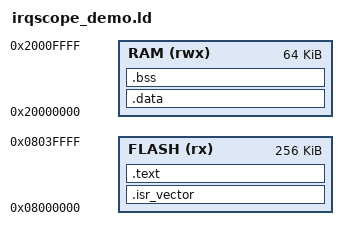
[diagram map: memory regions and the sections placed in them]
ENTRY(Reset_Handler)

MEMORY
{
    FLASH (rx)  : ORIGIN = 0x08000000, LENGTH = 256K
    RAM   (rwx) : ORIGIN = 0x20000000, LENGTH = 64K
}

__stack_top = ORIGIN(RAM) + LENGTH(RAM);

SECTIONS
{
    .isr_vector ORIGIN(FLASH) : ALIGN(128)
    {
        KEEP(*(.isr_vector))
    } > FLASH

    .text : ALIGN(4)
    {
        *(.text*)
        *(.rodata*)
        . = ALIGN(4);
        _etext = .;
    } > FLASH

    .data : AT(_etext)
    {
        _sdata = .;
        *(.data*)
        _edata = .;
    } > RAM

    .bss (NOLOAD) :
    {
        _sbss = .;
        *(.bss*)
        *(COMMON)
        _ebss = .;
    } > RAM

    /DISCARD/ : { *(.comment*) *(.note*) *(.eh_frame*) }
}
